# ESP32-P4 register map
Vendor: ESPRESSIF SYSTEMS (SHANGHAI) CO., LTD.; Series: ESP32 P-Series; File version: 3
CPU: RV32IMAFC r0p0, little endian, no MPU, FPU, 0 interrupt priority bits
Address unit: 32 bits
Registers are 32-bit, read-write, reset 0x0 unless marked. A register's access mark holds for its fields unless they carry their own. Offsets are from the block's base; [hi:lo] are bit positions; {n}, {i} and the like mark numbered series; 'fields as' and 'values as' point back to an identical list.

## IO_MUX — Input/Output Multiplexer
Base 0x500E1000
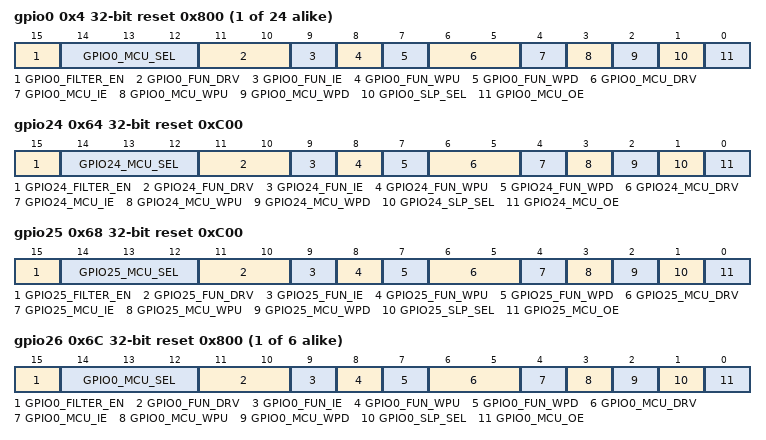
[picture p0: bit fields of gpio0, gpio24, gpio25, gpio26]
{0x4+4i} gpio{i} reset 0x800 (i=0..23) — iomux control register for gpio{i}
  [15] GPIO{i}_FILTER_EN — input filter enable
  [14:12] GPIO{i}_MCU_SEL — 0:select function0, 1:select function1 ...
  [11:10] GPIO{i}_FUN_DRV — select drive strenth, 0:5mA, 1:10mA, 2:20mA, 3:40mA
  [9] GPIO{i}_FUN_IE — input enable
  [8] GPIO{i}_FUN_WPU — pull-up enable
  [7] GPIO{i}_FUN_WPD — pull-down enable
  [6:5] GPIO{i}_MCU_DRV — select drive strenth on sleep mode
  [4] GPIO{i}_MCU_IE — input enable on sleep mode
  [3] GPIO{i}_MCU_WPU — pull-up enable on sleep mode
  [2] GPIO{i}_MCU_WPD — pull-down enable on sleep mode
  [1] GPIO{i}_SLP_SEL — io sleep mode enable. set 1 to enable sleep mode.
  [0] GPIO{i}_MCU_OE — output enable on sleep mode
0x64 gpio24 reset 0xC00 — iomux control register for gpio24
  [15] GPIO24_FILTER_EN — input filter enable
  [14:12] GPIO24_MCU_SEL — 0:select function0, 1:select function1 ...
  [11:10] GPIO24_FUN_DRV — select drive strenth, 0:5mA, 1:10mA, 2:20mA, 3:40mA
  [9] GPIO24_FUN_IE — input enable
  [8] GPIO24_FUN_WPU — pull-up enable
  [7] GPIO24_FUN_WPD — pull-down enable
  [6:5] GPIO24_MCU_DRV — select drive strenth on sleep mode
  [4] GPIO24_MCU_IE — input enable on sleep mode
  [3] GPIO24_MCU_WPU — pull-up enable on sleep mode
  [2] GPIO24_MCU_WPD — pull-down enable on sleep mode
  [1] GPIO24_SLP_SEL — io sleep mode enable. set 1 to enable sleep mode.
  [0] GPIO24_MCU_OE — output enable on sleep mode
0x68 gpio25 reset 0xC00 — iomux control register for gpio25
  [15] GPIO25_FILTER_EN — input filter enable
  [14:12] GPIO25_MCU_SEL — 0:select function0, 1:select function1 ...
  [11:10] GPIO25_FUN_DRV — select drive strenth, 0:5mA, 1:10mA, 2:20mA, 3:40mA
  [9] GPIO25_FUN_IE — input enable
  [8] GPIO25_FUN_WPU — pull-up enable
  [7] GPIO25_FUN_WPD — pull-down enable
  [6:5] GPIO25_MCU_DRV — select drive strenth on sleep mode
  [4] GPIO25_MCU_IE — input enable on sleep mode
  [3] GPIO25_MCU_WPU — pull-up enable on sleep mode
  [2] GPIO25_MCU_WPD — pull-down enable on sleep mode
  [1] GPIO25_SLP_SEL — io sleep mode enable. set 1 to enable sleep mode.
  [0] GPIO25_MCU_OE — output enable on sleep mode
{0x4+4i} gpio{i} reset 0x800 (i=26..31) — iomux control register for gpio{i}
  fields as gpio0
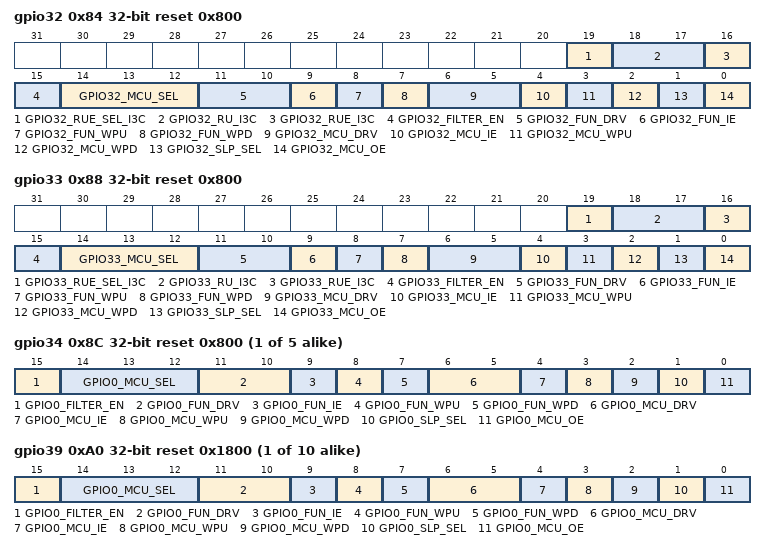
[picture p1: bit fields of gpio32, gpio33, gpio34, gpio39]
0x84 gpio32 reset 0x800 — iomux control register for gpio32
  [19] GPIO32_RUE_SEL_I3C
  [18:17] GPIO32_RU_I3C
  [16] GPIO32_RUE_I3C
  [15] GPIO32_FILTER_EN — input filter enable
  [14:12] GPIO32_MCU_SEL — 0:select function0, 1:select function1 ...
  [11:10] GPIO32_FUN_DRV — select drive strenth, 0:5mA, 1:10mA, 2:20mA, 3:40mA
  [9] GPIO32_FUN_IE — input enable
  [8] GPIO32_FUN_WPU — pull-up enable
  [7] GPIO32_FUN_WPD — pull-down enable
  [6:5] GPIO32_MCU_DRV — select drive strenth on sleep mode
  [4] GPIO32_MCU_IE — input enable on sleep mode
  [3] GPIO32_MCU_WPU — pull-up enable on sleep mode
  [2] GPIO32_MCU_WPD — pull-down enable on sleep mode
  [1] GPIO32_SLP_SEL — io sleep mode enable. set 1 to enable sleep mode.
  [0] GPIO32_MCU_OE — output enable on sleep mode
0x88 gpio33 reset 0x800 — iomux control register for gpio33
  [19] GPIO33_RUE_SEL_I3C
  [18:17] GPIO33_RU_I3C
  [16] GPIO33_RUE_I3C
  [15] GPIO33_FILTER_EN — input filter enable
  [14:12] GPIO33_MCU_SEL — 0:select function0, 1:select function1 ...
  [11:10] GPIO33_FUN_DRV — select drive strenth, 0:5mA, 1:10mA, 2:20mA, 3:40mA
  [9] GPIO33_FUN_IE — input enable
  [8] GPIO33_FUN_WPU — pull-up enable
  [7] GPIO33_FUN_WPD — pull-down enable
  [6:5] GPIO33_MCU_DRV — select drive strenth on sleep mode
  [4] GPIO33_MCU_IE — input enable on sleep mode
  [3] GPIO33_MCU_WPU — pull-up enable on sleep mode
  [2] GPIO33_MCU_WPD — pull-down enable on sleep mode
  [1] GPIO33_SLP_SEL — io sleep mode enable. set 1 to enable sleep mode.
  [0] GPIO33_MCU_OE — output enable on sleep mode
{0x4+4i} gpio{i} reset 0x800 (i=34..38) — iomux control register for gpio{i}
  fields as gpio0
{0x4+4i} gpio{i} reset 0x1800 (i=39..48) — iomux control register for gpio{i}
  fields as gpio0
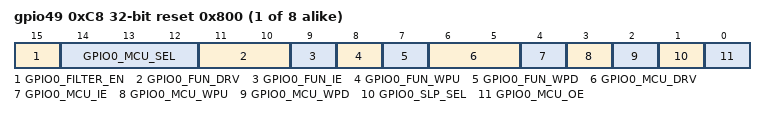
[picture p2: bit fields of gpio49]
{0x4+4i} gpio{i} reset 0x800 (i=49..56) — iomux control register for gpio{i}
  fields as gpio0
0x104 DATE reset 0x201222 — iomux version
  [27:0] DATE — csv date
